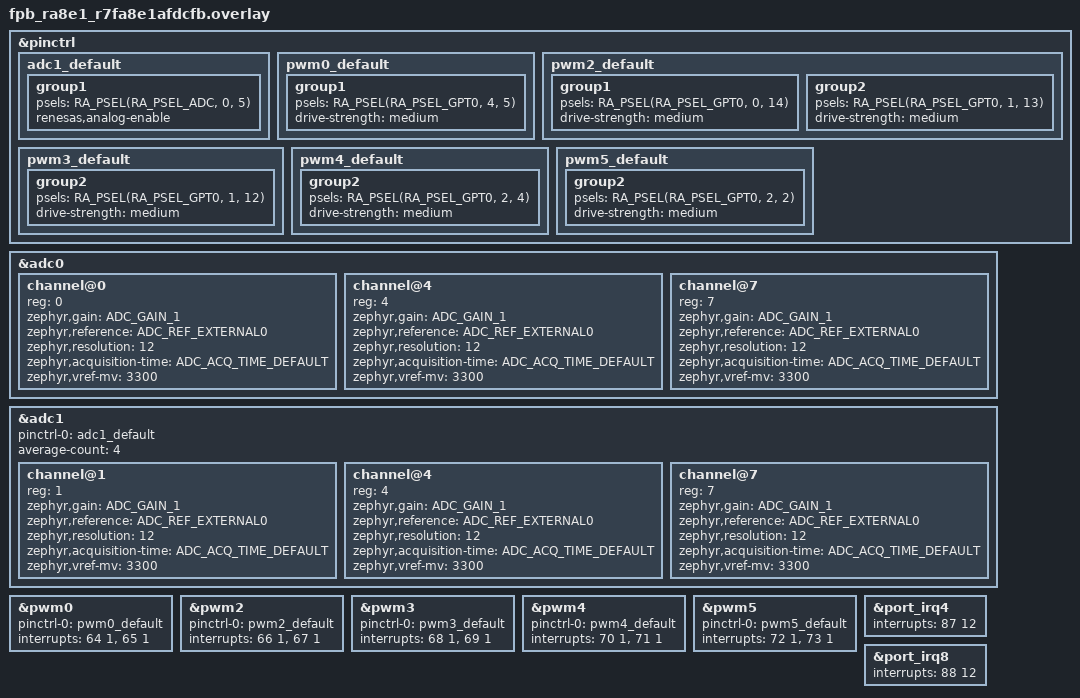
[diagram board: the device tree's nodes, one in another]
/*
 * Copyright (c) 2026 TOKITA Hiroshi
 *
 * SPDX-License-Identifier: Apache-2.0
 */

&pinctrl {
	adc1_default: adc1_default {
		group1 {
			/* input */
			psels = <RA_PSEL(RA_PSEL_ADC, 0, 5)>;
			renesas,analog-enable;
		};
	};

	pwm0_default: pwm0_default {
		group1 {
			/* GTIOC0A */
			psels = <RA_PSEL(RA_PSEL_GPT0, 4, 5)>;
			drive-strength = "medium";
		};
	};

	pwm2_default: pwm2_default {
		group1 {
			/* GTIOC2A */
			psels = <RA_PSEL(RA_PSEL_GPT0, 0, 14)>;
			drive-strength = "medium";
		};

		group2 {
			/* GTIOC2B */
			psels = <RA_PSEL(RA_PSEL_GPT0, 1, 13)>;
			drive-strength = "medium";
		};
	};

	pwm3_default: pwm3_default {
		group2 {
			/* GTIOC3B */
			psels = <RA_PSEL(RA_PSEL_GPT0, 1, 12)>;
			drive-strength = "medium";
		};
	};
	pwm4_default: pwm4_default {
		group2 {
			/* GTIOC4B */
			psels = <RA_PSEL(RA_PSEL_GPT0, 2, 4)>;
			drive-strength = "medium";
		};
	};
	pwm5_default: pwm5_default {
		group2 {
			/* GTIOC5B */
			psels = <RA_PSEL(RA_PSEL_GPT0, 2, 2)>;
			drive-strength = "medium";
		};
	};
};

&adc0 {
	status = "okay";
	#address-cells = <1>;
	#size-cells = <0>;

	channel@0 {
		reg = <0>;
		zephyr,gain = "ADC_GAIN_1";
		zephyr,reference = "ADC_REF_EXTERNAL0";
		zephyr,resolution = <12>;
		zephyr,acquisition-time = <ADC_ACQ_TIME_DEFAULT>;
		zephyr,vref-mv = <3300>;
	};

	channel@4 {
		reg = <4>;
		zephyr,gain = "ADC_GAIN_1";
		zephyr,reference = "ADC_REF_EXTERNAL0";
		zephyr,resolution = <12>;
		zephyr,acquisition-time = <ADC_ACQ_TIME_DEFAULT>;
		zephyr,vref-mv = <3300>;
	};

	channel@7 {
		reg = <7>;
		zephyr,gain = "ADC_GAIN_1";
		zephyr,reference = "ADC_REF_EXTERNAL0";
		zephyr,resolution = <12>;
		zephyr,acquisition-time = <ADC_ACQ_TIME_DEFAULT>;
		zephyr,vref-mv = <3300>;
	};
};

&adc1 {
	pinctrl-0 = <&adc1_default>;
	pinctrl-names = "default";
	average-count = <4>;
	#address-cells = <1>;
	#size-cells = <0>;
	status = "okay";

	channel@1 {
		reg = <1>;
		zephyr,gain = "ADC_GAIN_1";
		zephyr,reference = "ADC_REF_EXTERNAL0";
		zephyr,resolution = <12>;
		zephyr,acquisition-time = <ADC_ACQ_TIME_DEFAULT>;
		zephyr,vref-mv = <3300>;
	};

	channel@4 {
		reg = <4>;
		zephyr,gain = "ADC_GAIN_1";
		zephyr,reference = "ADC_REF_EXTERNAL0";
		zephyr,resolution = <12>;
		zephyr,acquisition-time = <ADC_ACQ_TIME_DEFAULT>;
		zephyr,vref-mv = <3300>;
	};

	channel@7 {
		reg = <7>;
		zephyr,gain = "ADC_GAIN_1";
		zephyr,reference = "ADC_REF_EXTERNAL0";
		zephyr,resolution = <12>;
		zephyr,acquisition-time = <ADC_ACQ_TIME_DEFAULT>;
		zephyr,vref-mv = <3300>;
	};
};

&pwm0 {
	pinctrl-0 = <&pwm0_default>;
	pinctrl-names = "default";
	interrupts = <64 1>, <65 1>;
	interrupt-names = "gtioca", "overflow";
	status = "okay";
};

&pwm2 {
	pinctrl-0 = <&pwm2_default>;
	pinctrl-names = "default";
	interrupts = <66 1>, <67 1>;
	interrupt-names = "gtioca", "overflow";
	status = "okay";
};

&pwm3 {
	pinctrl-0 = <&pwm3_default>;
	pinctrl-names = "default";
	interrupts = <68 1>, <69 1>;
	interrupt-names = "gtioca", "overflow";
	status = "okay";
};

&pwm4 {
	pinctrl-0 = <&pwm4_default>;
	pinctrl-names = "default";
	interrupts = <70 1>, <71 1>;
	interrupt-names = "gtioca", "overflow";
	status = "okay";
};

&pwm5 {
	pinctrl-0 = <&pwm5_default>;
	pinctrl-names = "default";
	interrupts = <72 1>, <73 1>;
	interrupt-names = "gtioca", "overflow";
	status = "okay";
};

&port_irq4 {
	interrupts = <87 12>;
	status = "okay";
};

&port_irq8 {
	interrupts = <88 12>;
	status = "okay";
};
